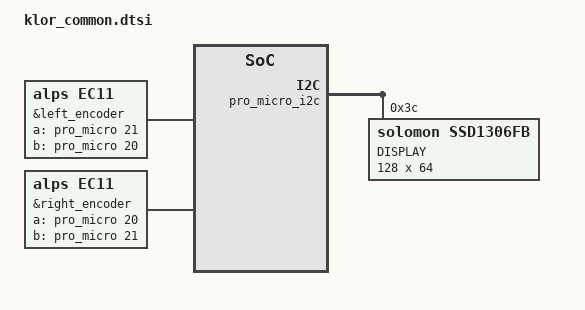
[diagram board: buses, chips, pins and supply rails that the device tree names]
/*
 * Copyright (c) 2022 The ZMK Contributors
 *
 * SPDX-License-Identifier: MIT
 */

#include <dt-bindings/zmk/matrix_transform.h>

/ {
	chosen {
		zephyr,display = &oled;
		zmk,kscan = &kscan0;
		zmk,matrix_transform = &default_transform;
	};

	kscan0: kscan {
		compatible = "zmk,kscan-gpio-matrix";
		label = "KSCAN";

		diode-direction = "col2row";		
	};

	/ {
    sensors {
        compatible = "zmk,keymap-sensors";
        sensors = <&left_encoder &right_encoder>;
        triggers-per-rotation = <20>; // Adjust based on your encoder resolution
    };
};

&left_encoder {
    status = "okay";
    compatible = "alps,ec11";
    a-gpios = <&pro_micro 21 (GPIO_ACTIVE_HIGH | GPIO_PULL_UP)>;
    b-gpios = <&pro_micro 20 (GPIO_ACTIVE_HIGH | GPIO_PULL_UP)>;
    steps = <24>;
    #sensor-binding-cells = <1>;
};

&right_encoder {
    status = "okay";
    compatible = "alps,ec11";
    a-gpios = <&pro_micro 20 (GPIO_ACTIVE_HIGH | GPIO_PULL_UP)>;
    b-gpios = <&pro_micro 21 (GPIO_ACTIVE_HIGH | GPIO_PULL_UP)>;
    steps = <24>;
    #sensor-binding-cells = <1>;
};

	sensors {
		compatible = "zmk,keymap-sensors";
		sensors = <&left_encoder &right_encoder>;
	};

	// TODO: RGB node(s)
};

&pro_micro_i2c {
	status = "okay";

	oled: ssd1306@3c {
		compatible = "solomon,ssd1306fb";
		reg = <0x3c>;
		label = "DISPLAY";
		width = <128>;
		height = <64>;
		segment-offset = <0>;
		page-offset = <0>;
		display-offset = <0>;
		multiplex-ratio = <63>;
		prechargep = <0x22>;
      		inversion-on;
	};
};
